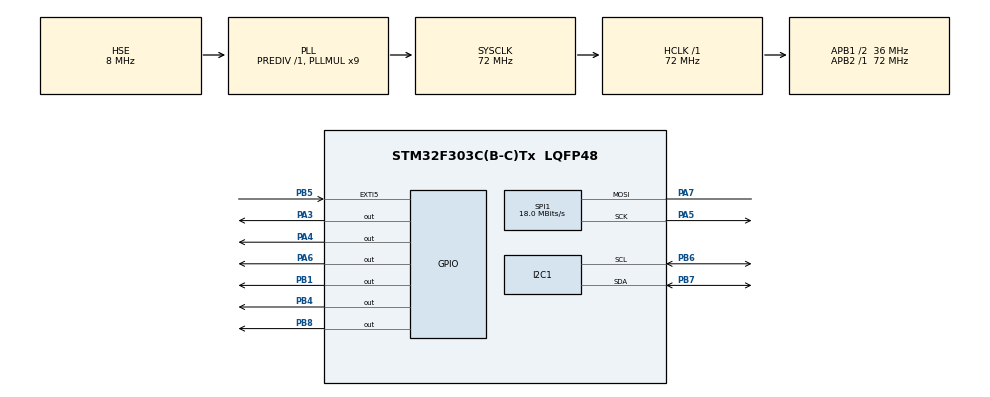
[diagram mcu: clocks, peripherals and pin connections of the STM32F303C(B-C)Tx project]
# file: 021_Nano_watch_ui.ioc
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I2C1.Timing=0x00201D2B
Mcu.Family=STM32F3
Mcu.Name=STM32F303C(B-C)Tx
Mcu.Package=LQFP48
NVIC.EXTI9_5_IRQn=true\:0\:0\:false\:false\:true\:true\:true\:true
NVIC.PriorityGroup=NVIC_PRIORITYGROUP_4
PA3.Signal=GPIO_Output
PA4.Signal=GPIO_Output
PA5.Mode=Simplex_Bidirectional_Master
PA5.Signal=SPI1_SCK
PA6.Signal=GPIO_Output
PA7.Mode=Simplex_Bidirectional_Master
PA7.Signal=SPI1_MOSI
PB1.Signal=GPIO_Output
PB4.Signal=GPIO_Output
PB5.Signal=GPXTI5
PB6.Mode=I2C
PB6.Signal=I2C1_SCL
PB7.Mode=I2C
PB7.Signal=I2C1_SDA
PB8.Signal=GPIO_Output
PF0-OSC_IN.Mode=HSE-External-Oscillator
PF0-OSC_IN.Signal=RCC_OSC_IN
PF1-OSC_OUT.Mode=HSE-External-Oscillator
PF1-OSC_OUT.Signal=RCC_OSC_OUT
ProjectManager.HeapSize=0x200
ProjectManager.StackSize=0x400
ProjectManager.TargetToolchain=STM32CubeIDE
RCC.AHBFreq_Value=72000000
RCC.APB1CLKDivider=RCC_HCLK_DIV2
RCC.APB1Freq_Value=36000000
RCC.APB1TimFreq_Value=72000000
RCC.APB2Freq_Value=72000000
RCC.APB2TimFreq_Value=72000000
RCC.CortexFreq_Value=72000000
RCC.HCLKFreq_Value=72000000
RCC.HSE_VALUE=8000000
RCC.HSI_VALUE=8000000
RCC.LSE_VALUE=32768
RCC.PLLMUL=RCC_PLL_MUL9
RCC.PLLSourceVirtual=RCC_PLLSOURCE_HSE
RCC.SYSCLKFreq_VALUE=72000000
RCC.SYSCLKSourceVirtual=RCC_SYSCLKSOURCE_PLLCLK
RCC.USBFreq_Value=72000000
SPI1.BaudRatePrescaler=SPI_BAUDRATEPRESCALER_4
SPI1.CalculateBaudRate=18.0 MBits/s
SPI1.DataSize=SPI_DATASIZE_8BIT
SPI1.Direction=SPI_DIRECTION_1LINE
SPI1.Mode=SPI_MODE_MASTER
SPI1.VirtualType=VM_MASTER
board=custom

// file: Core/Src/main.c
/* USER CODE BEGIN Header */
/**
  ******************************************************************************
  * @file           : main.c
  * @brief          : Main program body
  ******************************************************************************
  * @attention
  *
  * Copyright (c) 2024 STMicroelectronics.
  * All rights reserved.
  *
  * This software is licensed under terms that can be found in the LICENSE file
  * in the root directory of this software component.
  * If no LICENSE file comes with this software, it is provided AS-IS.
  *
  ******************************************************************************
  */
/* USER CODE END Header */
#include "main.h"

/* USER CODE BEGIN Includes */
#include <string.h>
#include <stdio.h>
#include "math.h"
#include "app.h"
#include "error.h"
/* USER CODE END Includes */

I2C_HandleTypeDef hi2c1;

SPI_HandleTypeDef hspi1;

void SystemClock_Config(void);
static void MX_GPIO_Init(void);
static void MX_I2C1_Init(void);
static void MX_SPI1_Init(void);

int main(void)
{

  /* MCU Configuration--------------------------------------------------------*/

  /* Reset of all peripherals, Initializes the Flash interface and the Systick. */
  HAL_Init();

  /* Configure the system clock */
  SystemClock_Config();

  /* Initialize all configured peripherals */
  MX_GPIO_Init();
  MX_I2C1_Init();
  MX_SPI1_Init();
  /* USER CODE BEGIN 2 */
  if (app_init() != ERR_OK) {
    Error_Handler();
  }

  app_run();
  /* USER CODE END 2 */

  /* Infinite loop */
  while (1)
  {

  }
}

void SystemClock_Config(void)
{
  RCC_OscInitTypeDef RCC_OscInitStruct = {0};
  RCC_ClkInitTypeDef RCC_ClkInitStruct = {0};
  RCC_PeriphCLKInitTypeDef PeriphClkInit = {0};

  /** Initializes the RCC Oscillators according to the specified parameters
  * in the RCC_OscInitTypeDef structure.
  */
  RCC_OscInitStruct.OscillatorType = RCC_OSCILLATORTYPE_HSI|RCC_OSCILLATORTYPE_HSE;
  RCC_OscInitStruct.HSEState = RCC_HSE_ON;
  RCC_OscInitStruct.HSEPredivValue = RCC_HSE_PREDIV_DIV1;
  RCC_OscInitStruct.HSIState = RCC_HSI_ON;
  RCC_OscInitStruct.HSICalibrationValue = RCC_HSICALIBRATION_DEFAULT;
  RCC_OscInitStruct.PLL.PLLState = RCC_PLL_ON;
  RCC_OscInitStruct.PLL.PLLSource = RCC_PLLSOURCE_HSE;
  RCC_OscInitStruct.PLL.PLLMUL = RCC_PLL_MUL9;
  if (HAL_RCC_OscConfig(&RCC_OscInitStruct) != HAL_OK)
  {
    Error_Handler();
  }

  /** Initializes the CPU, AHB and APB buses clocks
  */
  RCC_ClkInitStruct.ClockType = RCC_CLOCKTYPE_HCLK|RCC_CLOCKTYPE_SYSCLK
                              |RCC_CLOCKTYPE_PCLK1|RCC_CLOCKTYPE_PCLK2;
  RCC_ClkInitStruct.SYSCLKSource = RCC_SYSCLKSOURCE_PLLCLK;
  RCC_ClkInitStruct.AHBCLKDivider = RCC_SYSCLK_DIV1;
  RCC_ClkInitStruct.APB1CLKDivider = RCC_HCLK_DIV2;
  RCC_ClkInitStruct.APB2CLKDivider = RCC_HCLK_DIV1;

  if (HAL_RCC_ClockConfig(&RCC_ClkInitStruct, FLASH_LATENCY_2) != HAL_OK)
  {
    Error_Handler();
  }
  PeriphClkInit.PeriphClockSelection = RCC_PERIPHCLK_I2C1;
  PeriphClkInit.I2c1ClockSelection = RCC_I2C1CLKSOURCE_HSI;
  if (HAL_RCCEx_PeriphCLKConfig(&PeriphClkInit) != HAL_OK)
  {
    Error_Handler();
  }
}

static void MX_I2C1_Init(void)
{

  hi2c1.Instance = I2C1;
  hi2c1.Init.Timing = 0x00201D2B;
  hi2c1.Init.OwnAddress1 = 0;
  hi2c1.Init.AddressingMode = I2C_ADDRESSINGMODE_7BIT;
  hi2c1.Init.DualAddressMode = I2C_DUALADDRESS_DISABLE;
  hi2c1.Init.OwnAddress2 = 0;
  hi2c1.Init.OwnAddress2Masks = I2C_OA2_NOMASK;
  hi2c1.Init.GeneralCallMode = I2C_GENERALCALL_DISABLE;
  hi2c1.Init.NoStretchMode = I2C_NOSTRETCH_DISABLE;
  if (HAL_I2C_Init(&hi2c1) != HAL_OK)
  {
    Error_Handler();
  }

  /** Configure Analogue filter
  */
  if (HAL_I2CEx_ConfigAnalogFilter(&hi2c1, I2C_ANALOGFILTER_ENABLE) != HAL_OK)
  {
    Error_Handler();
  }

  /** Configure Digital filter
  */
  if (HAL_I2CEx_ConfigDigitalFilter(&hi2c1, 0) != HAL_OK)
  {
    Error_Handler();
  }

}

static void MX_SPI1_Init(void)
{

  /* SPI1 parameter configuration*/
  hspi1.Instance = SPI1;
  hspi1.Init.Mode = SPI_MODE_MASTER;
  hspi1.Init.Direction = SPI_DIRECTION_1LINE;
  hspi1.Init.DataSize = SPI_DATASIZE_8BIT;
  hspi1.Init.CLKPolarity = SPI_POLARITY_LOW;
  hspi1.Init.CLKPhase = SPI_PHASE_1EDGE;
  hspi1.Init.NSS = SPI_NSS_SOFT;
  hspi1.Init.BaudRatePrescaler = SPI_BAUDRATEPRESCALER_2;
  hspi1.Init.FirstBit = SPI_FIRSTBIT_MSB;
  hspi1.Init.TIMode = SPI_TIMODE_DISABLE;
  hspi1.Init.CRCCalculation = SPI_CRCCALCULATION_DISABLE;
  hspi1.Init.CRCPolynomial = 7;
  hspi1.Init.CRCLength = SPI_CRC_LENGTH_DATASIZE;
  hspi1.Init.NSSPMode = SPI_NSS_PULSE_ENABLE;
  if (HAL_SPI_Init(&hspi1) != HAL_OK)
  {
    Error_Handler();
  }

}

static void MX_GPIO_Init(void)
{
  GPIO_InitTypeDef GPIO_InitStruct = {0};

  /* GPIO Ports Clock Enable */
  __HAL_RCC_GPIOF_CLK_ENABLE();
  __HAL_RCC_GPIOA_CLK_ENABLE();
  __HAL_RCC_GPIOB_CLK_ENABLE();

  /*Configure GPIO pin Output Level */
  HAL_GPIO_WritePin(GPIOA, GPIO_PIN_3|GPIO_PIN_4|GPIO_PIN_6, GPIO_PIN_RESET);

  /*Configure GPIO pin Output Level */
  HAL_GPIO_WritePin(GPIOB, GPIO_PIN_1|GPIO_PIN_4|GPIO_PIN_8, GPIO_PIN_RESET);

  /*Configure GPIO pins : PA3 PA4 PA6 */
  GPIO_InitStruct.Pin = GPIO_PIN_3|GPIO_PIN_4|GPIO_PIN_6;
  GPIO_InitStruct.Mode = GPIO_MODE_OUTPUT_PP;
  GPIO_InitStruct.Pull = GPIO_NOPULL;
  GPIO_InitStruct.Speed = GPIO_SPEED_FREQ_LOW;
  HAL_GPIO_Init(GPIOA, &GPIO_InitStruct);

  /*Configure GPIO pins : PB1 PB4 PB8 */
  GPIO_InitStruct.Pin = GPIO_PIN_1|GPIO_PIN_4|GPIO_PIN_8;
  GPIO_InitStruct.Mode = GPIO_MODE_OUTPUT_PP;
  GPIO_InitStruct.Pull = GPIO_NOPULL;
  GPIO_InitStruct.Speed = GPIO_SPEED_FREQ_LOW;
  HAL_GPIO_Init(GPIOB, &GPIO_InitStruct);

  /*Configure GPIO pin : PB5 */
  GPIO_InitStruct.Pin = GPIO_PIN_5;
  GPIO_InitStruct.Mode = GPIO_MODE_IT_RISING;
  GPIO_InitStruct.Pull = GPIO_NOPULL;
  HAL_GPIO_Init(GPIOB, &GPIO_InitStruct);

  /* EXTI interrupt init*/
  HAL_NVIC_SetPriority(EXTI9_5_IRQn, 0, 0);
  HAL_NVIC_EnableIRQ(EXTI9_5_IRQn);

}

void Error_Handler(void)
{
  __disable_irq();
  while (1)
  {
  }
}
